# LDC register map
Vendor: Texas Instruments
Peripheral module from a debugger description file (folder DRA74xP_75xP_76xP_77xP).
Registers are 32-bit, access per field, reset values left out (the file's numbers can be read two ways) unless marked. A register's access mark holds for its fields unless they carry their own. Offsets are as the file gives them; lines under a group give offsets from that group; [hi:lo] are bit positions; {n}, {i} and the like mark numbered series; 'fields as' and 'values as' point back to an identical list; <NAME> marks a mode.

## LDC
0x00 LDC_PID ro — IP Revision Identifier (X.Y.R) Used by software to track features, bugs, and compatibility
  [31:0] REVISION — IP Revision
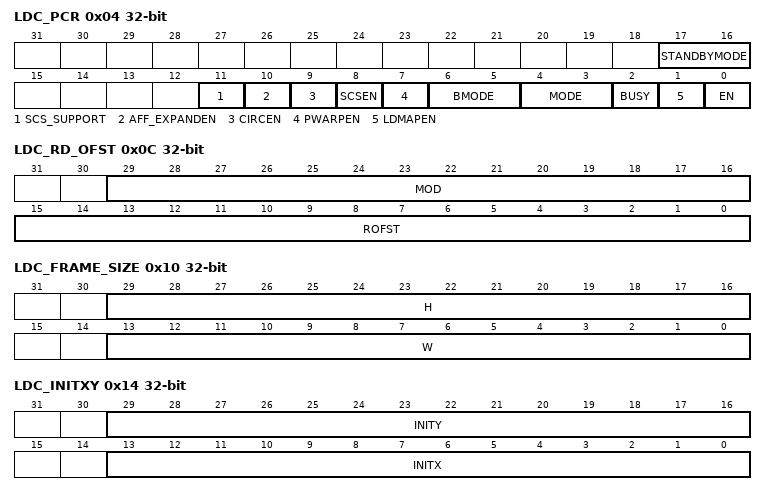
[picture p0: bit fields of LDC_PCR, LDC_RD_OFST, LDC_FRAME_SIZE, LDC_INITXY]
0x04 LDC_PCR — LDC Peripheral Control
  [17:16] STANDBYMODE rw — Configuration of the local initiator state management mode. By definition, initiator may generate read/write transaction as long as it is out of STANDBY state. 0x0 FORCE Force-standby mode: local initiator is unconditionally placed in standby state. Backup mode, for debug only. 0x1 NO No-standby mode: local initiator is unconditionally placed out of standby state. Backup mode, for debug only. 0x2 SMART Smart-standby mode: local initiator standby status depends on local conditions, i.e. the module's functional requirement from the initiator.
  [11] SCS_SUPPORT ro — Reports '1' if SCS feature is supported by LDC.
  [10] AFF_EXPANDEN rw — Enables expanded format of affine warp coefficients (A, B, D, and E). 0: A, B, D, E are treated as S14Q12 1: A, B, D, E are treated as S16Q12
  [9] CIRCEN rw — Enables circular addressing mode. 0 - Disable circular addressing for input data. 1 - Enable circular addressing.
  [8] SCSEN rw — Enable/Disable smart codec statistic (SCS) function. 0 - Disable SCS 1 - Enable SCS
  [7] PWARPEN rw — Enable perspective warp transform. Set to 1 to enable use ofLDC_GH[15:0] G and LDC_GH[31:16] H.
  [6:5] BMODE rw — Bayer data format (only applicable when MODE=1). 3: A-law data in/out, 2: Packed 8-bit data in/out, 1: Packed 12-bit data in/out, 0: Unpacked 12-bit data in/out
  [4:3] MODE rw — 2: YCbCr 4:2:0 Lens Distortion, 1: Bayer chromatic aberration mode, 0: YCbCr 4:2:2 Lens Distortion
  [2] BUSY ro — Idle/busy status, 0: Idle, 1: Busy, asserted when function is started, cleared when function is complete
  [1] LDMAPEN rw — LD Mapping Enable, 1: Enabled, 0: Disabled
  [0] EN rw — Write 1 to start the function, as specified in MODE
0x08 LDC_RD_BASE rw — LDC Read Frame Base
  [31:0] RBASE — Read frame base, must be 16-byte aligned so internally [3:0] bits are hard-wired zero.
0x0C LDC_RD_OFST
  [29:16] MOD rw — Sets the circular buffer size if circular buffering mode is used. The circular buffer is sized in terms of number of rows.
  [15:0] ROFST rw — Read frame line offset, must be 16-byte aligned so internally [3:0] bits are hard-wired zero.
0x10 LDC_FRAME_SIZE
  [29:16] H rw — Frame number of lines
  [13:0] W rw — Frame width
0x14 LDC_INITXY — LDC Initial XY
  [29:16] INITY rw — Output starting Y-coordinate (must be even)
  [13:0] INITX rw — Output starting X-coordiinate (must be even)
0x18 LDC_WR_BASE rw — LDC Write Frame Base
  [31:0] WBASE — Write frame base, must be 16-byte aligned so internally [3:0] bits are hard-wired zero.
0x1C LDC_WR_OFST — LDC Write Frame Line Offset
  [15:0] WOFST rw — Write frame line offset, must be 16-byte aligned so internally [3:0] bits are hard-wired zero.
0x20 LDC_420C_RD_BASE rw — LDC Read Frame Base For Cb/Cr in 420 Mode
  [31:0] RBASE — Read frame base for Cb/Cr in 420 mode, must be 16-byte aligned so internally [3:0] bits are hard-wired zero
0x24 LDC_420C_WR_BASE rw — LDC Write Frame Base for Cb/Cr in 420 Mode
  [31:0] WBASE — Write frame base for Cb/Cr in 420 mode, must be 16-byte aligned so internally [3:0] bits are hard-wired zero
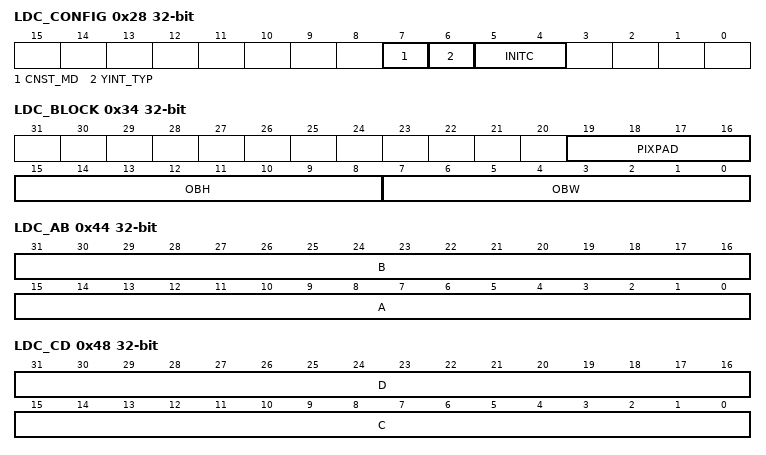
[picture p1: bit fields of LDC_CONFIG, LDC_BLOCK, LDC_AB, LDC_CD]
0x28 LDC_CONFIG — LDC Configuration
  [7] CNST_MD rw — Constant output address mode
  [6] YINT_TYP rw — Interpolation type for Y data, 0: bicubic, 1: bilinear
  [5:4] INITC rw — Initial color for LD back mapping (Bayer mode only), 0: R, 1: Gr, 2: Gb, 3: B
0x34 LDC_BLOCK — LDC Block Size
  [19:16] PIXPAD rw — Pixel pad (must be greater than 1)
  [15:8] OBH rw — Output block height (must be 0 and even)
  [7:0] OBW rw — Output block width (must be 0 and multiple of 8 in 422 mode or in 420 mode, 16, or in Bayer mode, 8, 16, or 32 depending on Bayer format)
0x44 LDC_AB rw — LDC Affine Transwarp A/B
  [31:16] B — Affine transwarp B (S16Q12)
  [15:0] A — Affine transwarp A (S16Q12)
0x48 LDC_CD rw — LDC Affine Transwarp C/D
  [31:16] D — Affine transwarp D (S16Q12)
  [15:0] C — Affine transwarp C (S16Q3)
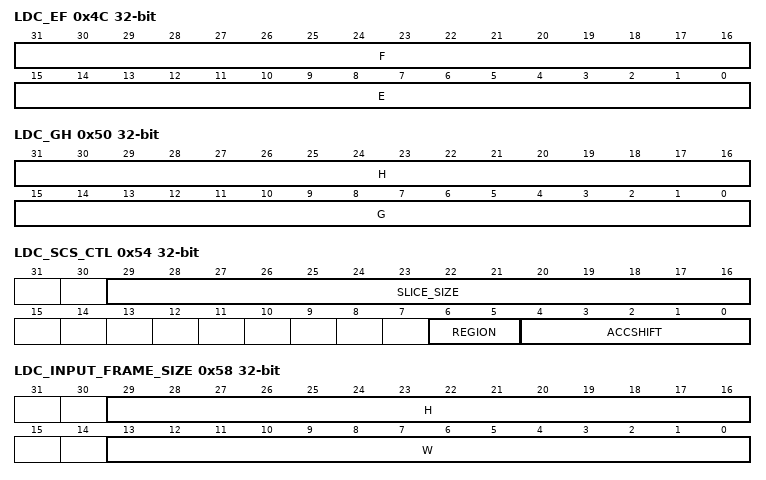
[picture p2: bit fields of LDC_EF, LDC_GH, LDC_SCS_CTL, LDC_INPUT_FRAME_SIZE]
0x4C LDC_EF rw — LDC Affine Transwarp EF
  [31:16] F — Affine transwarp F (S16Q3)
  [15:0] E — Affine transwarp E (S16Q12)
0x50 LDC_GH rw — LDC Perspective Transformation Parameters, G and H
  [31:16] H — Perspective Transformation H (S16Q23)
  [15:0] G — Perspective Transformation G (S16Q23)
0x54 LDC_SCS_CTL — Define number of regions and output divider for region based statistics.
  [29:16] SLICE_SIZE rw — Sets the number of output lines computed by LDC before the computed macroblock row statistics are transferred to system memory. This must be a multiple of 16 so bits [19:16] are internally fixed to zero. The maximum possible value is 8176 (0x1FF0).
  [6:5] REGION rw — Sets the number of regions in both directions for the region based statistics. Possible values: 0 - 1x1 1 - 2x2 2 - 3x3 3 - 4x4
  [4:0] ACCSHIFT rw — Sets the output divider for sum of pixels in a region and sum of squares of pixels in a region. This parameter right shifts the final accumulator prior to writing the output statistics.
0x58 LDC_INPUT_FRAME_SIZE — Defines the total input frame size.
  [29:16] H rw — Height of input image.
  [13:0] W rw — Width of input image.
0x5C LDC_MESHTABLE_BASE rw — Read address for mesh offset table.
  [31:0] BASE — Read address for mesh offset table. (Must be 16-byte aligned so four LSB are coded to 0)
0x60 LDC_MESHTABLE_OFST — Defines the stride between rows for the offset table (in bytes).
  [15:0] OFST rw — LDC Mesh table line offset, must be 16-byte aligned so internally [3:0] bits are hard-wired zero.
0x64 LDC_MESHTABLE_CONFIG — Defines the downsampling factors used for the mesh offset tables.
  [2:0] M rw — Mesh table downsampling factor. 0: 1 - no downsampling 1: 2 - 2x downsampling 2: 4 3: 8 4: 16 5: 32 6: 64 7: 128
